# PIC32CX2051BZ66048 device description
Architecture: CORTEX-M4; Family: PIC32CX; Series: PIC32CXBZ66
Registers are 32-bit, read-write, reset 0x0 unless marked. A register's access mark holds for its fields unless they carry their own. Offsets are from the block's base; [hi:lo] are bit positions; {n}, {i} and the like mark numbered series.

## FREQM — Frequency Meter
Instances: FREQM 0x40000400
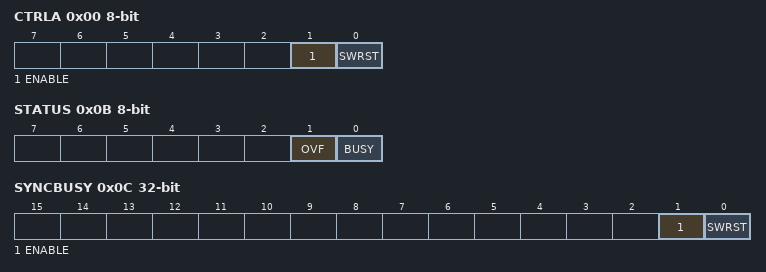
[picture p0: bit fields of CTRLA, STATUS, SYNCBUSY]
0x00 CTRLA 8-bit — Control A Register
  [1] ENABLE
  [0] SWRST — Software Reset
0x01 CTRLB 8-bit wo — Control B Register
  [0] START — Start Measurement
0x02 CFGA 16-bit — Config A register
  [7:0] REFNUM — Number of Reference Clock Cycles
0x08 INTENCLR 8-bit (atomic clear) — Interrupt Enable Clear Register
  [0] DONE — Measurement Done Interrupt Enable
0x09 INTENSET 8-bit (atomic set) — Interrupt Enable Set Register
  [0] DONE — Measurement Done Interrupt Enable
0x0A INTFLAG 8-bit (atomic clear) — Interrupt Flag Register
  [0] DONE — Measurement Done
0x0B STATUS 8-bit
  [1] OVF — Sticky Count Value Overflow
  [0] BUSY — FREQM Status
0x0C SYNCBUSY ro — Synchronization Busy Register
  [1] ENABLE
  [0] SWRST — Software Reset
0x10 VALUE ro — Count Value Register
  [23:0] VALUE — Measurement Value

## GPIO
Instances: GPIOE 0x44002D00, GPIOD 0x44002C00, GPIOC 0x44002B00, GPIOB 0x44002A00, GPIOA 0x44002900
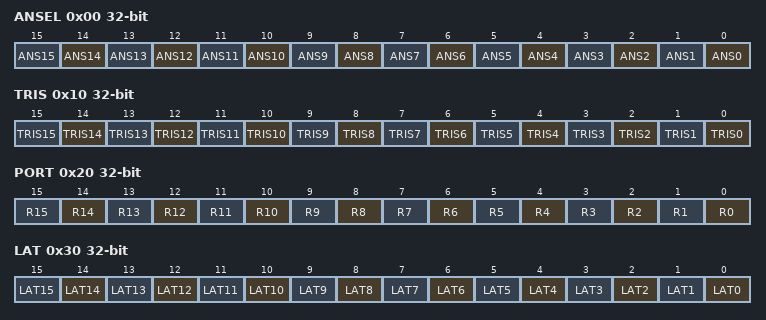
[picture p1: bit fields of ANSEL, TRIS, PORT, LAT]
0x00 ANSEL
  [n] ANS{n} (n=0..15)
0x04 ANSELCLR
0x08 ANSELSET
0x0C ANSELINV
0x10 TRIS
  [n] TRIS{n} (n=0..15)
0x14 TRISCLR
0x18 TRISSET
0x1C TRISINV
0x20 PORT
  [n] R{n} (n=0..15)
0x24 PORTCLR
0x28 PORTSET
0x2C PORTINV
0x30 LAT
  [n] LAT{n} (n=0..15)
0x34 LATCLR
0x38 LATSET
0x3C LATINV
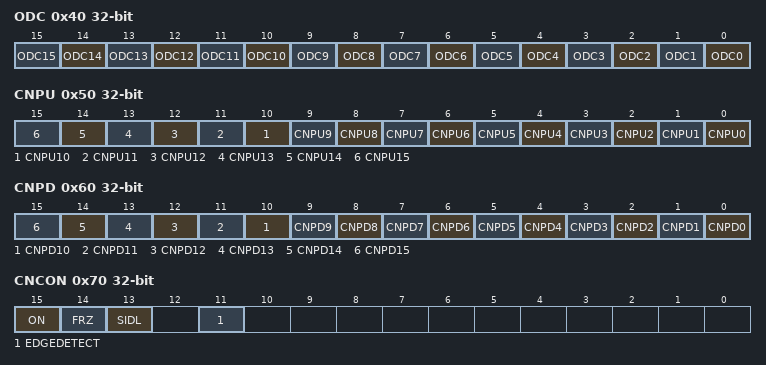
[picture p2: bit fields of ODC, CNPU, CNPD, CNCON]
0x40 ODC
  [n] ODC{n} (n=0..15)
0x44 ODCCLR
0x48 ODCSET
0x4C ODCINV
0x50 CNPU
  [n] CNPU{n} (n=0..15)
0x54 CNPUCLR
0x58 CNPUSET
0x5C CNPUINV
0x60 CNPD
  [n] CNPD{n} (n=0..15)
0x64 CNPDCLR
0x68 CNPDSET
0x6C CNPDINV
0x70 CNCON
  [15] ON, [14] FRZ, [13] SIDL, [11] EDGEDETECT
0x74 CNCONCLR
0x78 CNCONSET
0x7C CNCONINV
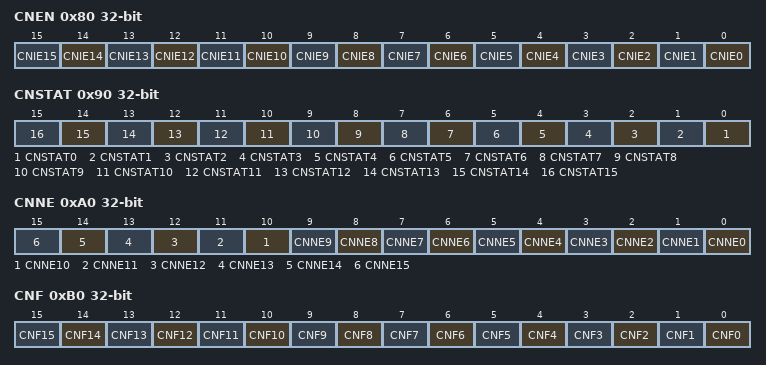
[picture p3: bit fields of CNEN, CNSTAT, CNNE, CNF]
0x80 CNEN
  [n] CNIE{n} (n=0..15)
0x84 CNENCLR
0x88 CNENSET
0x8C CNENINV
0x90 CNSTAT
  [n] CNSTAT{n} (n=0..15)
0x94 CNSTATCLR
0x98 CNSTATSET
0x9C CNSTATINV
0xA0 CNNE
  [n] CNNE{n} (n=0..15)
0xA4 CNNECLR
0xA8 CNNESET
0xAC CNNEINV
0xB0 CNF
  [n] CNF{n} (n=0..15)
0xB4 CNFCLR
0xB8 CNFSET
0xBC CNFINV
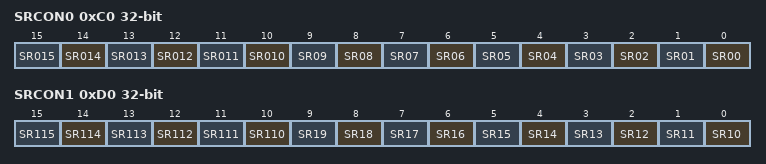
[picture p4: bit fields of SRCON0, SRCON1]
0xC0 SRCON0
  [n] SR{n:03} (n=10..15), [n] SR{n:02} (n=0..9)
0xC4 SRCON0CLR
0xC8 SRCON0SET
0xCC SRCON0INV
0xD0 SRCON1
  [n-100] SR{n} (n=110..115), [n-10] SR{n} (n=10..19)
0xD4 SRCON1CLR
0xD8 SRCON1SET
0xDC SRCON1INV

## HMATRIX2TOP — HSB Matrix
Instances: HMATRIX2TOP 0x42002400
0x80 PRAS0 reset 0x3 — Priority part A for Target 0
0x84 PRBS0 — Priority part B for Target 0
0x88 PRAS1 reset 0x30000300 — Priority part A for Target 1
0x8C PRBS1 — Priority part B for Target 1
0x90 PRAS2 reset 0x3330000 — Priority part A for Target 2
0x94 PRBS2 reset 0x300 — Priority part B for Target 2
0x98 PRAS3 reset 0x3000 — Priority part A for Target 3
0x9C PRBS3 reset 0x33 — Priority part B for Target 3
0xA0 PRAS4 reset 0x30 — Priority part A for Target 4
{0x84+8i} PRBS{i} (i=4..13) — Priority part B for Target {i}
0xA8 PRAS5 reset 0x330303 — Priority part A for Target 5
{0x80+8i} PRAS{i} reset 0x33303 (i=6..9) — Priority part A for Target {i}
0xD0 PRAS10 reset 0x333330 — Priority part A for Target 10
0xD8 PRAS11 reset 0x30 — Priority part A for Target 11
0xE0 PRAS12 reset 0x333303 — Priority part A for Target 12
0xE8 PRAS13 reset 0x33303 — Priority part A for Target 13

## NVM — flash controller
Instances: NVM 0x44000600
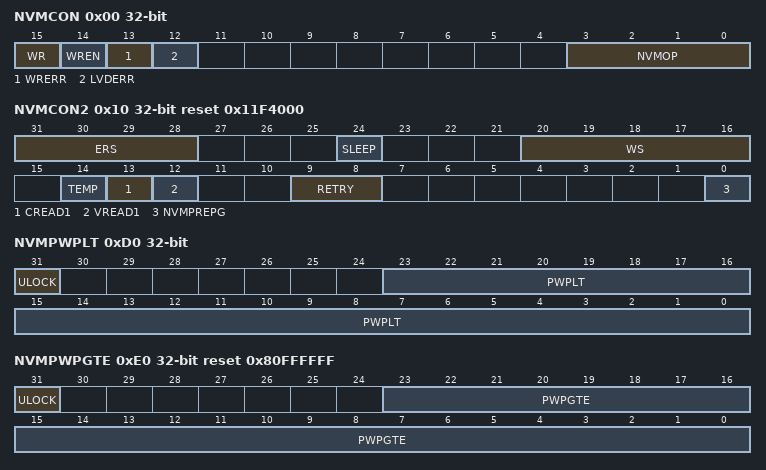
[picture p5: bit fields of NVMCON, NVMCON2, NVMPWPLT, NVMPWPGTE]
0x00 NVMCON
  [15] WR, [14] WREN, [13] WRERR, [12] LVDERR, [3:0] NVMOP
0x04 NVMCONCLR
0x08 NVMCONSET
0x0C NVMCONINV
0x10 NVMCON2 reset 0x11F4000
  [31:28] ERS, [24] SLEEP, [20:16] WS, [14] TEMP, [13] CREAD1, [12] VREAD1, [9:8] RETRY, [0] NVMPREPG
0x14 NVMCON2CLR
0x18 NVMCON2SET
0x1C NVMCON2INV
0x20 NVMKEY
0x30 NVMADDR
{0x40+0x10*i} NVMDATA{i} (i=0..7)
0xC0 NVMSRCADDR
0xD0 NVMPWPLT
  [31] ULOCK, [23:0] PWPLT
0xD4 NVMPWPLTCLR
0xD8 NVMPWPLTSET
0xDC NVMPWPLTINV
0xE0 NVMPWPGTE reset 0x80FFFFFF
  [31] ULOCK, [23:0] PWPGTE
0xE4 NVMPWPGTECLR
0xE8 NVMPWPGTESET
0xEC NVMPWPGTEINV
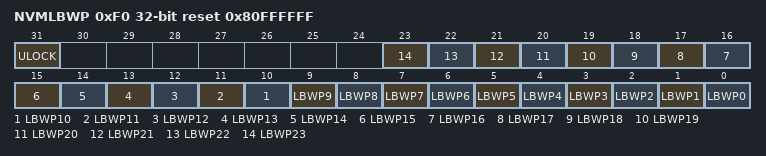
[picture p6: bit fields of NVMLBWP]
0xF0 NVMLBWP reset 0x80FFFFFF
  [31] ULOCK, [n] LBWP{n} (n=0..23)
0xF4 NVMLBWPCLR
0xF8 NVMLBWPSET
0xFC NVMLBWPINV
